# N32G430 register map
Vendor: Nationstech Ltd.; File version: 1.0
Registers are 32-bit, read-write, reset 0x0 unless marked. A register's access mark holds for its fields unless they carry their own. Offsets are from the block's base; [hi:lo] are bit positions; {n}, {i} and the like mark numbered series; 'fields as' and 'values as' point back to an identical list.

## ADC — analog to digital converter
Base 0x40020800
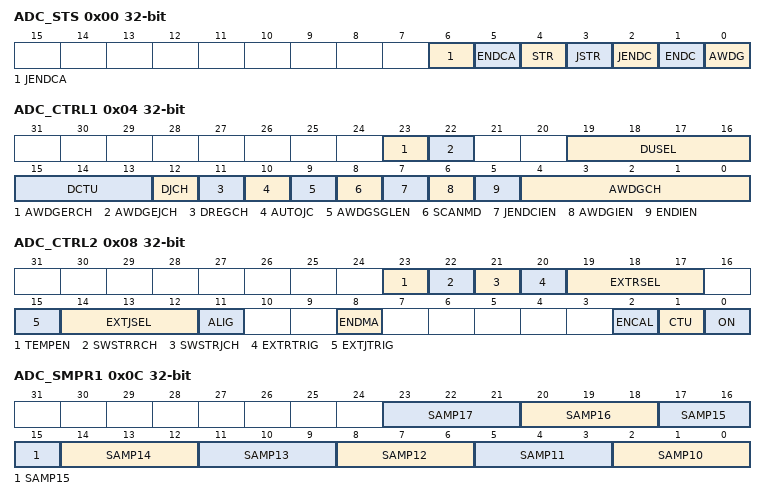
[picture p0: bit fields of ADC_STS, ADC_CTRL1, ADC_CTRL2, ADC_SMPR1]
0x00 ADC_STS
  [6] JENDCA, [5] ENDCA, [4] STR, [3] JSTR, [2] JENDC, [1] ENDC, [0] AWDG
0x04 ADC_CTRL1
  [23] AWDGERCH, [22] AWDGEJCH, [19:16] DUSEL, [15:13] DCTU, [12] DJCH, [11] DREGCH, [10] AUTOJC, [9] AWDGSGLEN, [8] SCANMD, [7] JENDCIEN, [6] AWDGIEN, [5] ENDIEN, [4:0] AWDGCH
0x08 ADC_CTRL2
  [23] TEMPEN, [22] SWSTRRCH, [21] SWSTRJCH, [20] EXTRTRIG, [19:17] EXTRSEL, [15] EXTJTRIG, [14:12] EXTJSEL, [11] ALIG, [8] ENDMA, [2] ENCAL, [1] CTU, [0] ON
0x0C ADC_SMPR1
  [3n-28:3n-30] SAMP{n} (n=10..17)
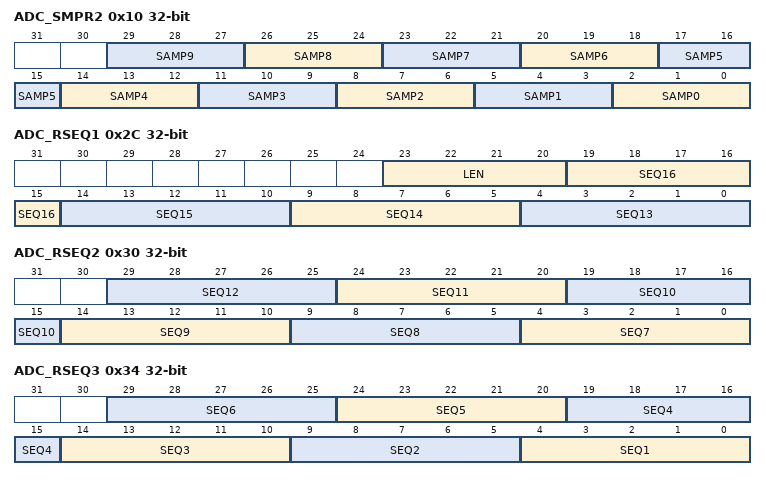
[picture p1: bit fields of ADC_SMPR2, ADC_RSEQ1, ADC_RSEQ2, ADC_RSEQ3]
0x10 ADC_SMPR2
  [3n+2:3n] SAMP{n} (n=0..9)
{0x10+4i} ADC_JOFFSET{i} (i=1..4)
  [11:0] OFFSETJCH{i}
0x24 ADC_WDGHIGH
  [15:0] HTH
0x28 ADC_WDGLOW
  [15:0] LTH
0x2C ADC_RSEQ1
  [23:20] LEN, [5n-61:5n-65] SEQ{n} (n=13..16)
0x30 ADC_RSEQ2
  [5n-31:5n-35] SEQ{n} (n=7..12)
0x34 ADC_RSEQ3
  [5n-1:5n-5] SEQ{n} (n=1..6)
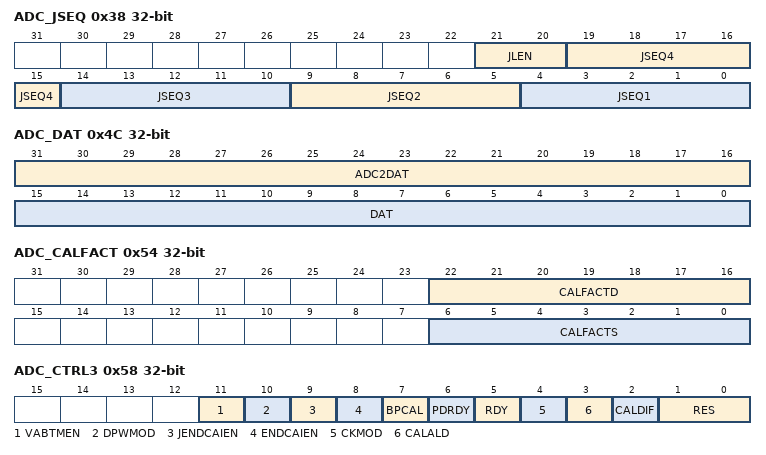
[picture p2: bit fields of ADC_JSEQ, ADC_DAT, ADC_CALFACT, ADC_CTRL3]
0x38 ADC_JSEQ
  [21:20] JLEN, [5n-1:5n-5] JSEQ{n} (n=1..4)
{0x38+4i} ADC_JDAT{i} (i=1..4)
  [15:0] JDAT{i}
0x4C ADC_DAT (reset mask 0xFFFF)
  [31:16] ADC2DAT, [15:0] DAT
0x50 ADC_DIFSEL
  [18:1] DIFSEL
0x54 ADC_CALFACT
  [22:16] CALFACTD, [6:0] CALFACTS
0x58 ADC_CTRL3
  [11] VABTMEN, [10] DPWMOD, [9] JENDCAIEN, [8] ENDCAIEN, [7] BPCAL, [6] PDRDY, [5] RDY, [4] CKMOD, [3] CALALD, [2] CALDIF, [1:0] RES
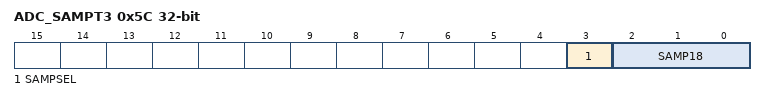
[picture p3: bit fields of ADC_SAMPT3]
0x5C ADC_SAMPT3
  [3] SAMPSEL, [2:0] SAMP18

## CAN — Controller area network
Base 0x40006400
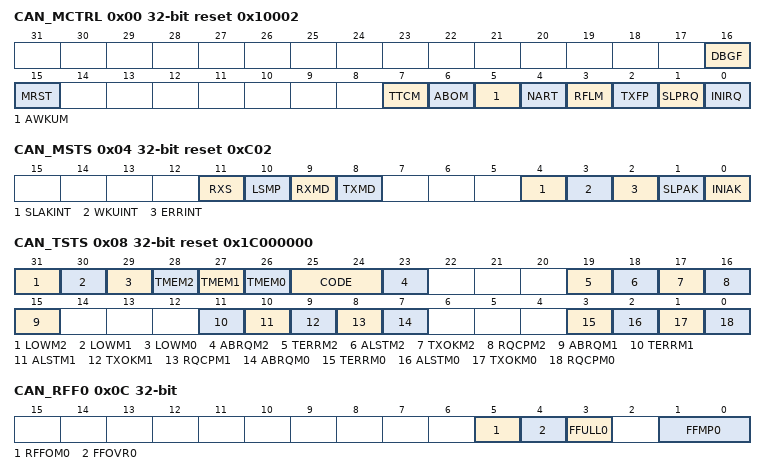
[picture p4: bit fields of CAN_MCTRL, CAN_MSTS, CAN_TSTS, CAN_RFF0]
0x00 CAN_MCTRL reset 0x10002
  [16] DBGF, [15] MRST, [7] TTCM, [6] ABOM, [5] AWKUM, [4] NART, [3] RFLM, [2] TXFP, [1] SLPRQ, [0] INIRQ
0x04 CAN_MSTS reset 0xC02
  [11] RXS, [10] LSMP, [9] RXMD, [8] TXMD, [4] SLAKINT, [3] WKUINT, [2] ERRINT, [1] SLPAK, [0] INIAK
0x08 CAN_TSTS reset 0x1C000000
  [31] LOWM2, [30] LOWM1, [29] LOWM0, [28] TMEM2, [27] TMEM1, [26] TMEM0, [25:24] CODE, [23] ABRQM2, [19] TERRM2, [18] ALSTM2, [17] TXOKM2, [16] RQCPM2, [15] ABRQM1, [11] TERRM1, [10] ALSTM1, [9] TXOKM1, [8] RQCPM1, [7] ABRQM0, [3] TERRM0, [2] ALSTM0, [1] TXOKM0, [0] RQCPM0
0x0C CAN_RFF0
  [5] RFFOM0, [4] FFOVR0, [3] FFULL0, [1:0] FFMP0
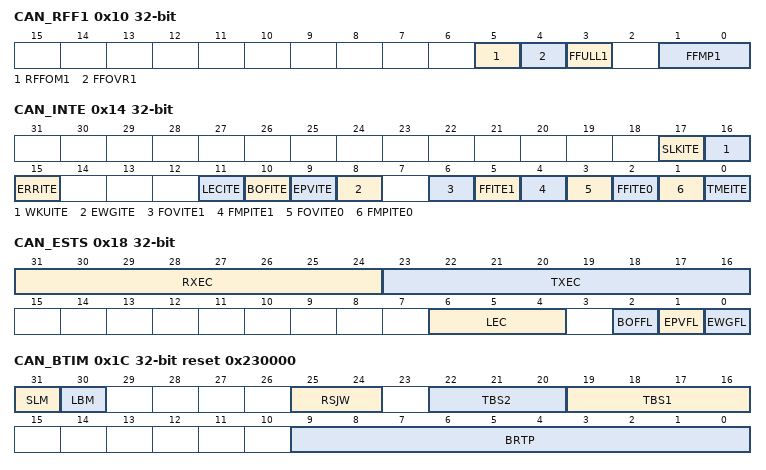
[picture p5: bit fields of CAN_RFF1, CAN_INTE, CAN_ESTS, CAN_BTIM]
0x10 CAN_RFF1
  [5] RFFOM1, [4] FFOVR1, [3] FFULL1, [1:0] FFMP1
0x14 CAN_INTE
  [17] SLKITE, [16] WKUITE, [15] ERRITE, [11] LECITE, [10] BOFITE, [9] EPVITE, [8] EWGITE, [6] FOVITE1, [5] FFITE1, [4] FMPITE1, [3] FOVITE0, [2] FFITE0, [1] FMPITE0, [0] TMEITE
0x18 CAN_ESTS
  [31:24] RXEC, [23:16] TXEC, [6:4] LEC, [2] BOFFL, [1] EPVFL, [0] EWGFL
0x1C CAN_BTIM reset 0x230000
  [31] SLM, [30] LBM, [25:24] RSJW, [22:20] TBS2, [19:16] TBS1, [9:0] BRTP
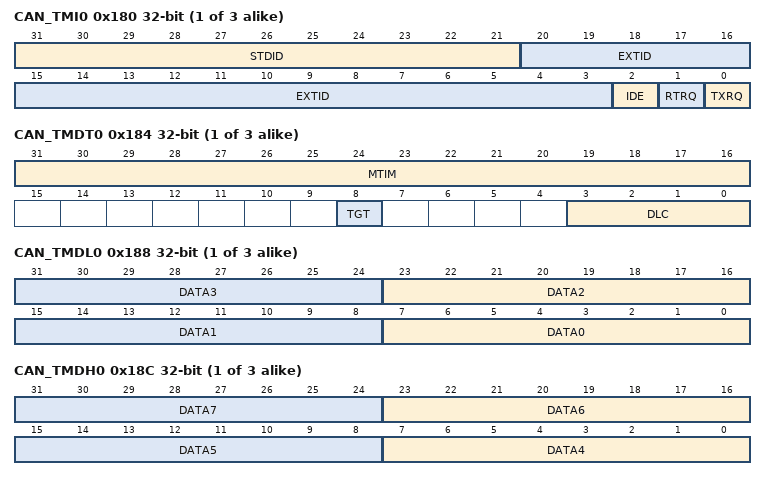
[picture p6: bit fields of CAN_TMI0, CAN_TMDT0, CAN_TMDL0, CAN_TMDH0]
{0x180+0x10*i} CAN_TMI{i} (i=0..2)
  [31:21] STDID, [20:3] EXTID, [2] IDE, [1] RTRQ, [0] TXRQ
{0x184+0x10*i} CAN_TMDT{i} (i=0..2)
  [31:16] MTIM, [8] TGT, [3:0] DLC
{0x188+0x10*i} CAN_TMDL{i} (i=0..2)
  [8n+7:8n] DATA{n} (n=0..3)
{0x18C+0x10*i} CAN_TMDH{i} (i=0..2)
  [8n-25:8n-32] DATA{n} (n=4..7)
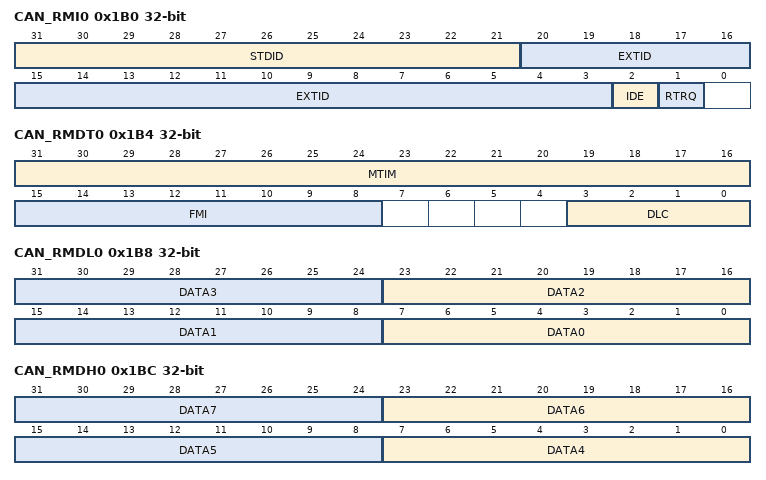
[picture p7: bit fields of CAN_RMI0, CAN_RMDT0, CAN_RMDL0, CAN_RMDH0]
0x1B0 CAN_RMI0
  [31:21] STDID, [20:3] EXTID, [2] IDE, [1] RTRQ
0x1B4 CAN_RMDT0
  [31:16] MTIM, [15:8] FMI, [3:0] DLC
0x1B8 CAN_RMDL0
  [8n+7:8n] DATA{n} (n=0..3)
0x1BC CAN_RMDH0
  [8n-25:8n-32] DATA{n} (n=4..7)
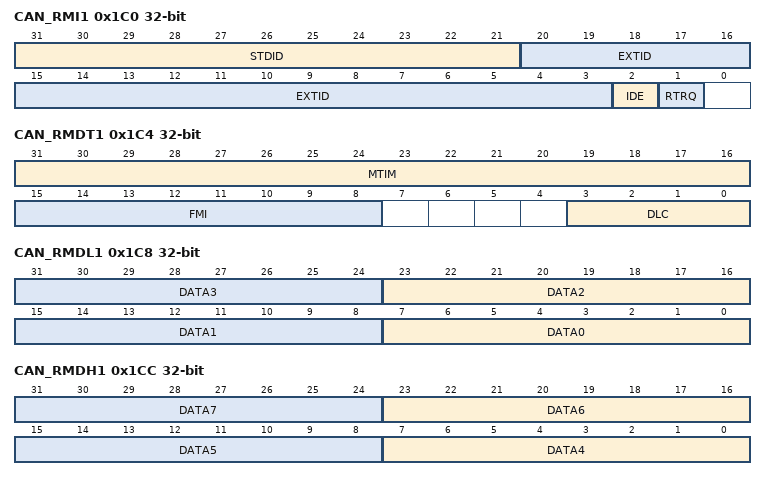
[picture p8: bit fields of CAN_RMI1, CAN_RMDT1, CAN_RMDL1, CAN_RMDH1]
0x1C0 CAN_RMI1
  [31:21] STDID, [20:3] EXTID, [2] IDE, [1] RTRQ
0x1C4 CAN_RMDT1
  [31:16] MTIM, [15:8] FMI, [3:0] DLC
0x1C8 CAN_RMDL1
  [8n+7:8n] DATA{n} (n=0..3)
0x1CC CAN_RMDH1
  [8n-25:8n-32] DATA{n} (n=4..7)
0x200 CAN_FMC reset 0x1
  [0] FINITM
0x204 CAN_FM1
  [13:0] FB
0x20C CAN_FS1
  [13:0] FSC
0x214 CAN_FFA1
  [13:0] FAF
0x21C CAN_FA1
  [13:0] FAC
{0x240+8i} CAN_F{i}B1 (i=0..13)
  [31:0] FBC
{0x244+8i} CAN_F{i}B2 (i=0..13)
  [31:0] FBC

## COMP — comparator
Base 0x40002400
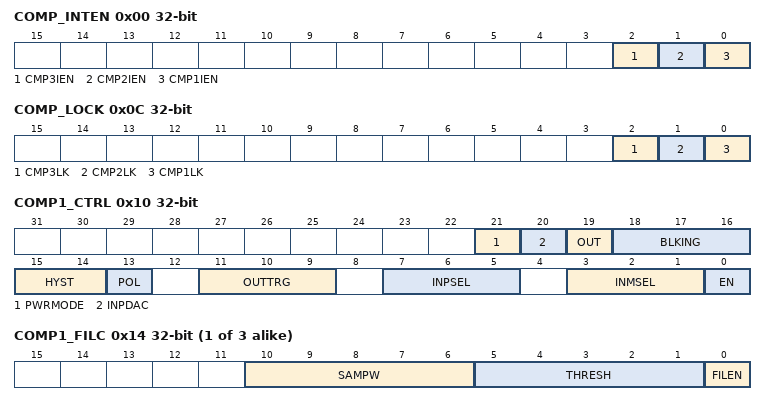
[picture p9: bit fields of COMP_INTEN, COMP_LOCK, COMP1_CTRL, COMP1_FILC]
0x00 COMP_INTEN
  [2] CMP3IEN, [1] CMP2IEN, [0] CMP1IEN
0x04 COMP_LPCKSEL
  [0] LPCKSEL
0x08 COMP_WINMODE
  [0] CMP12MD
0x0C COMP_LOCK
  [2] CMP3LK, [1] CMP2LK, [0] CMP1LK
0x10 COMP1_CTRL
  [21] PWRMODE, [20] INPDAC, [19] OUT, [18:16] BLKING, [15:14] HYST, [13] POL, [11:9] OUTTRG, [7:5] INPSEL, [3:1] INMSEL, [0] EN
{0x4+0x10*i} COMP{i}_FILC (i=1..3)
  [10:6] SAMPW, [5:1] THRESH, [0] FILEN
{0x8+0x10*i} COMP{i}_FILP (i=1..3)
  [15:0] CLKPSC
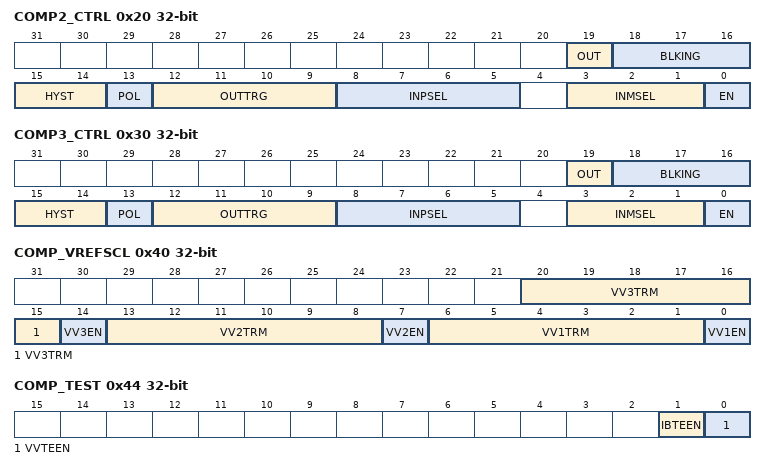
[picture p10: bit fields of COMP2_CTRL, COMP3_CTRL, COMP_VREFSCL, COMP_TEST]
0x20 COMP2_CTRL
  [19] OUT, [18:16] BLKING, [15:14] HYST, [13] POL, [12:9] OUTTRG, [8:5] INPSEL, [3:1] INMSEL, [0] EN
0x2C COMP2_OSEL
  [0] CMP2XO
0x30 COMP3_CTRL
  fields as COMP2_CTRL
0x40 COMP_VREFSCL
  [20:15] VV3TRM, [14] VV3EN, [13:8] VV2TRM, [7] VV2EN, [6:1] VV1TRM, [0] VV1EN
0x44 COMP_TEST
  [1] IBTEEN, [0] VVTEEN
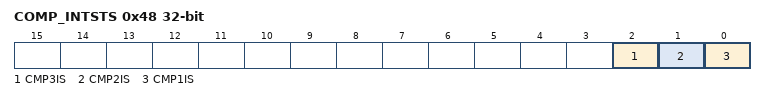
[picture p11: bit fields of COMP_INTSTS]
0x48 COMP_INTSTS
  [2] CMP3IS, [1] CMP2IS, [0] CMP1IS
